# nrf9220_application register map
Vendor: Nordic Semiconductor; Series: nRF92; File version: 1
CPU: CM33 r1p0, little endian, MPU, FPU, 3 interrupt priority bits, 480 interrupts, 4 SAU regions
Registers are 32-bit, read-write, reset 0x0 unless marked. A register's access mark holds for its fields unless they carry their own. Offsets are from the block's base; [hi:lo] are bit positions; lines under a group give offsets from that group; {n}, {i} and the like mark numbered series.

## BICR_NS — Board information configuration registers
Base 0x0FFF0800; alternate view of UICR_NS
0x00 POWER group — Unspecified
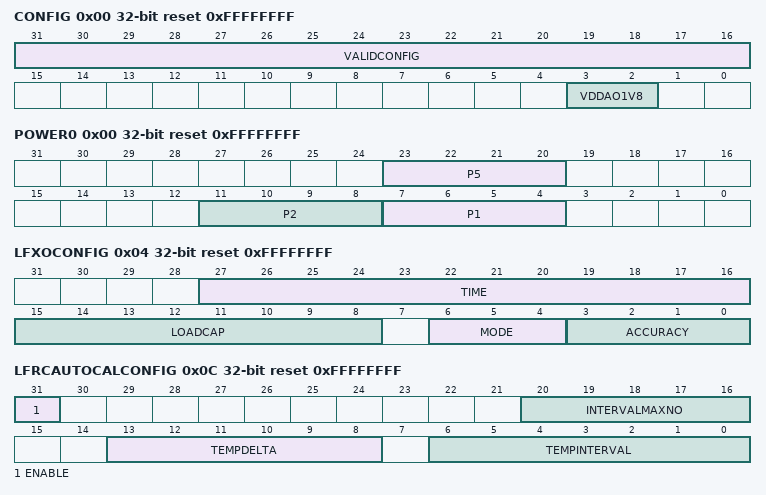
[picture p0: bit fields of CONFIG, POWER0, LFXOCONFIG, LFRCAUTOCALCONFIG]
  0x00 CONFIG reset 0xFFFFFFFF — Power configuration of power rails.
    [31:16] VALIDCONFIG — Indication of valid configuration for this register.
      0xFFFF=Invalid (This register is not programmed with valid content. Any other value than the value for valid.); 0xAC53=Valid (This register is programmed with valid content.)
    [3:2] VDDAO1V8 — VDD_AO_1V8 power configuration.
      3=Unconfigured (Power rail is unconfigured.); 0=Internal (Power rail is configured to use the internal regulator. This option requires the presence of an inductor for the 1V8 DCDC regulator.); 1=External (Power rail is configured to be externally powered.)
0x04 IOPORT group — Unspecified
  0x00 POWER0 reset 0xFFFFFFFF — Power configuration for P0 to P7 IO ports. Note: P0 is not included in the fields of this register because it is always internally supplied. The nominal maximum and limited output current levels of the device internal GPIO power switch are specified in the Electrical specification.
    [all] fields
      15=Unconfigured (Port supply is unconfigured.); 0=Disconnected (Port supply rail is not connected. Port cannot be used.); 1=External (Port supply is provided externally.); 2=SwExtHigh (Port supply is provided by the device internal GPIO power switch (1V8_OUT), configured for nominal maximum output current. The output current is shared between all ports supplied by the switch. Supply is powered down in System OFF. In System ON IDLE, the idle floor current increases significantly. System ON ALL IDLE entry is prevented.); 3=SwExtLow (Port supply is provided by the device internal GPIO power switch (1V8_OUT), configured for limited output current. The output current is shared between all ports supplied by the switch. Supply is powered down in System OFF. The idle floor current in System ON IDLE and System ON ALL IDLE is not affected.)
    [23:20] P5 — P5 power configuration.
    [11:8] P2 — P2 power configuration.
    [7:4] P1 — P1 power configuration.
  0x08 DRIVECTRL0 reset 0xFFFFFFFF — Drive control configuration for P0 to P7 IO ports.
    [23:20] P5 — P5 drive control configuration.
      15=Unconfigured (Port supply is unconfigured. PORTCNF.DRIVECTRL will not be adjusted.); 0=Ohms33 (PORTCNF.DRIVECTRL will be adjusted for 33 Ohms.); 1=Ohms40 (PORTCNF.DRIVECTRL will be adjusted for 40 Ohms.); 2=Ohms50 (PORTCNF.DRIVECTRL will be adjusted for 50 Ohms.); 3=Ohms66 (PORTCNF.DRIVECTRL will be adjusted for 66 Ohms.); 4=Ohms100 (PORTCNF.DRIVECTRL will be adjusted for 100 Ohms.)
0x14 LFOSC group — Unspecified
  0x00 CONFIG reset 0xFFFFFFFF — LF oscillator configuration. Note. This configuration might be overridden by MICR configuration.
    [3:0] SRC — LF oscillator source.
      15=Unconfigured (LF oscillator source is unconfigured. Default will be used.); 0=LFXO (Use LFXO as source for the LF oscillator.); 1=LFRC (Use LFRC as source for the LF oscillator.); 2=LFLPRC (Use LFLPRC as source for the LF oscillator.); 3=Synth (Use LF Synth as source for the LF oscillator.)
  0x04 LFXOCONFIG reset 0xFFFFFFFF — LFXO configuration. Note. This configuration might be overridden by MICR configuration.
    [27:16] TIME — LFXO startup time in ms.
      0xFFF=Unconfigured (Startup time has not been configured.)
    [15:8] LOADCAP — Built-in load capacitors selection in 1 pF steps. Max. value 25 pF.
      255=Unconfigured (The built-in load capacitors is unconfigured. LFXO will not start unless LOADCAP is configured.); 0=External (Do not use the built-in load capacitors, only external capacitors will be used.)
    [6:4] MODE — LFXO mode. LFXO will not start unless MODE is configured. Setting this field to anyting but Unconfigured will be used as the indication that the selected source is available as input to the LFXO.
      7=Unconfigured (The mode is unconfigured.); 0=Pierce (LFXO Pierce mode.); 1=PIXO (LFXO PIXO mode. NOT SUPPORTED); 2=ExtSine (LFXO in external sine wave mode.); 3=ExtSquare (LFXO in external square wave mode.)
    [3:0] ACCURACY — LFXO crystal or external signal accuracy.
      15=Unconfigured (The accuracy is unconfigured.); 0=500ppm (LFXO crystal or external signal has an accuracy of 500 ppm.); 1=250ppm (LFXO crystal or external signal has an accuracy of 250 ppm.); 2=150ppm (LFXO crystal or external signal has an accuracy of 150 ppm.); 3=100ppm (LFXO crystal or external signal has an accuracy of 100 ppm.); 4=75ppm (LFXO crystal or external signal has an accuracy of 75 ppm.); 5=50ppm (LFXO crystal or external signal has an accuracy of 50 ppm.); 6=30ppm (LFXO crystal or external signal has an accuracy of 30 ppm.); 7=20ppm (LFXO crystal or external signal has an accuracy of 20 ppm.)
  0x08 LFXOCAL reset 0xFFFFFFFF — LFXO calibration needed. Must be written to 0xFFFFFFFF after any modification of the LFXO board circuit, load capacitance, or crystal swap. Note. This configuration might be overridden by MICR configuration.
    [31:0] LFXOCAL — LFXO calibration needed. Must be written to 0xFFFFFFFF after any modification of the LFXO board circuit, load capacitance, or crystal swap.
      0xFFFFFFFF=Calibrate the LFXO at startup
  0x0C LFRCAUTOCALCONFIG reset 0xFFFFFFFF — LFRC autocalibration configuration. Note. This configuration might be overridden by MICR configuration.
    [31] ENABLE — LFRC.AUTOCALCONFIG register enable.
      0=Enabled (LFRC.AUTOCALCONFIG register has been configured and can be used.); 1=Disabled (LFRC.AUTOCALCONFIG register has not been configured and cannot be used.)
    [20:16] INTERVALMAXNO — Maximum number of TEMPINTERVAL periods in between calibrations, independent of temperature changes.
    [13:8] TEMPDELTA — Temperature delta that should trigger a calibration in 0.25 degrees steps.
    [6:0] TEMPINTERVAL — Temperature measurement interval in 0.25 s steps.
0x2C HFXO64M group — Unspecified
  0x00 CONFIG reset 0xFFFFFFFF — HFXO64M configuration. Note. This configuration might be overridden by MICR configuration.
    [2:0] MODE — HFXO64M mode.
      7=Unconfigured (The mode is unconfigured.); 0=Normal operating mode; 1=TCXO (TCXO/bypass mode); {v}=Crystal{v} (Reserved value) (v=2..6)
  0x04 STARTUPTIME reset 0xFFFFFFFF — HFXO64M startup time in us. Note. This configuration might be overridden by MICR configuration.
    [31:0] TIME — HFXO64M startup time in us.
      0xFFFFFFFF=Unconfigured (Startup time has not been configured.)
0x34 TAMPC group — Unspecified
  0x00 TAMPERSWITCH reset 0xFFFFFFFF — Configuration for external tamper switch detector.
    [3:0] TAMPERSWITCH — Tamper switch enable.
      15=Disabled (Tamper switch is disabled.); 0=Enabled (Tamper switch is enabled.)
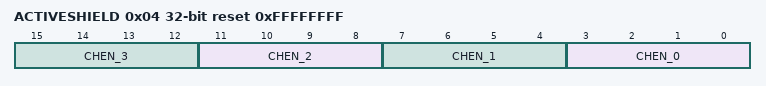
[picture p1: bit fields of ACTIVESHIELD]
  0x04 ACTIVESHIELD reset 0xFFFFFFFF — Configuration for active shield channels.
    [4n+3:4n] CHEN_{n} (n=0..3) — Active shield enable for channel {n}.
      15=Disabled (Active shield channel {n} is disabled.); 0=Enabled (Active shield channel {n} is enabled.)

## Notices in the file
Copyright (c) 2010 - 2026, Nordic Semiconductor ASA All rights reserved.
SPDX-License-Identifier: BSD-3-Clause
Redistribution and use in source and binary forms, with or without
modification, are permitted provided that the following conditions are met:
1. Redistributions of source code must retain the above copyright notice, this
list of conditions and the following disclaimer.
2. Redistributions in binary form must reproduce the above copyright
notice, this list of conditions and the following disclaimer in the
documentation and/or other materials provided with the distribution.
3. Neither the name of Nordic Semiconductor ASA nor the names of its
contributors may be used to endorse or promote products derived from this
software without specific prior written permission.
THIS SOFTWARE IS PROVIDED BY THE COPYRIGHT HOLDERS AND CONTRIBUTORS "AS IS"
AND ANY EXPRESS OR IMPLIED WARRANTIES, INCLUDING, BUT NOT LIMITED TO, THE
IMPLIED WARRANTIES OF MERCHANTABILITY, AND FITNESS FOR A PARTICULAR PURPOSE
ARE DISCLAIMED. IN NO EVENT SHALL NORDIC SEMICONDUCTOR ASA OR CONTRIBUTORS BE
LIABLE FOR ANY DIRECT, INDIRECT, INCIDENTAL, SPECIAL, EXEMPLARY, OR
CONSEQUENTIAL DAMAGES (INCLUDING, BUT NOT LIMITED TO, PROCUREMENT OF
SUBSTITUTE GOODS OR SERVICES; LOSS OF USE, DATA, OR PROFITS; OR BUSINESS
INTERRUPTION) HOWEVER CAUSED AND ON ANY THEORY OF LIABILITY, WHETHER IN
CONTRACT, STRICT LIABILITY, OR TORT (INCLUDING NEGLIGENCE OR OTHERWISE)
ARISING IN ANY WAY OUT OF THE USE OF THIS SOFTWARE, EVEN IF ADVISED OF THE
POSSIBILITY OF SUCH DAMAGE.
